AUTOSAR XML (schema 4-2-2)
package /ComponentTypes
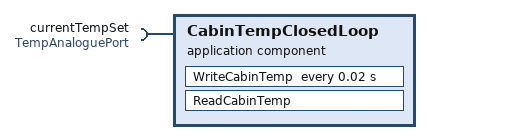
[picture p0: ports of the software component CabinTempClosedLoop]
  application sw component type CabinTempClosedLoop
    require port currentTempSet: required-interface=TempAnaloguePort
      required-com-specs:
        data-element=tempOut, filter=data-filter-type=ALWAYS, init-value=0
        data-element=tempIn, filter=data-filter-type=ALWAYS, init-value=0
    behavior CabinTempClosedLoop_InternalBehavior: data-type-mapping=tempMapSet
      data received event DRT_ReadCabinTemp_currentTempSet_tempIn: start-on-event=ReadCabinTemp, data=currentTempSet.tempIn
      timing event TMT_WriteCabinTemp: start-on-event=WriteCabinTemp, period=0.02
      runnable ReadCabinTemp
        data-receive-point-by-arguments:
          access REC_currentTempSet_tempIn: accessed-variable=currentTempSet.tempIn
      runnable WriteCabinTemp
        data-receive-point-by-arguments:
          access SEND_currentTempSet_tempOut: accessed-variable=currentTempSet.tempOut
  swc implementation CabinTempClosedLoop_Implementation: behavior=CabinTempClosedLoop_InternalBehavior
